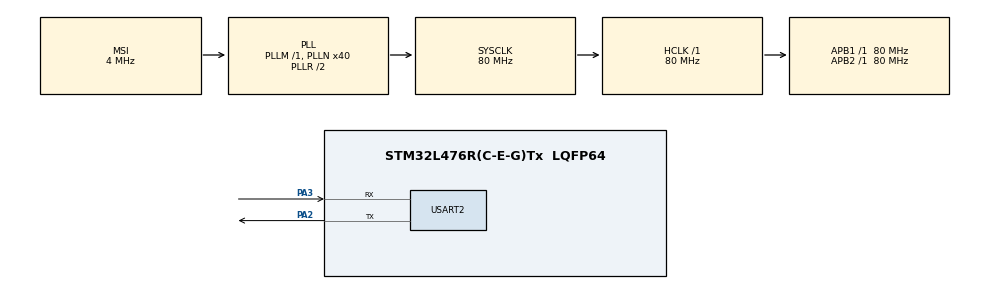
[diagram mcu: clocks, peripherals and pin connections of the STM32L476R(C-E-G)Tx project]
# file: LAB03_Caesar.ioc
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Mcu.Family=STM32L4
Mcu.Name=STM32L476R(C-E-G)Tx
Mcu.Package=LQFP64
NVIC.PriorityGroup=NVIC_PRIORITYGROUP_4
PA2.Mode=Asynchronous
PA2.Signal=USART2_TX
PA3.Mode=Asynchronous
PA3.Signal=USART2_RX
ProjectManager.HeapSize=0x200
ProjectManager.StackSize=0x400
ProjectManager.TargetToolchain=STM32CubeIDE
RCC.AHBFreq_Value=80000000
RCC.APB1Freq_Value=80000000
RCC.APB1TimFreq_Value=80000000
RCC.APB2Freq_Value=80000000
RCC.APB2TimFreq_Value=80000000
RCC.CortexFreq_Value=80000000
RCC.HCLKFreq_Value=80000000
RCC.HSE_VALUE=8000000
RCC.HSI_VALUE=16000000
RCC.LSE_VALUE=32768
RCC.MSI_VALUE=4000000
RCC.PLLN=40
RCC.SYSCLKFreq_VALUE=80000000
RCC.SYSCLKSource=RCC_SYSCLKSOURCE_PLLCLK
RCC.VCOOutputFreq_Value=160000000
USART2.VirtualMode-Asynchronous=VM_ASYNC
board=custom

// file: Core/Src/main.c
/* USER CODE BEGIN Header */
/**
 ******************************************************************************
 * @file           : main.c
 * @brief          : Main program body
 ******************************************************************************
 * @attention
 *
 * Copyright (c) 2023 STMicroelectronics.
 * All rights reserved.
 *
 * This software is licensed under terms that can be found in the LICENSE file
 * in the root directory of this software component.
 * If no LICENSE file comes with this software, it is provided AS-IS.
 *
 ******************************************************************************
 */
/* USER CODE END Header */
#include "main.h"

/* USER CODE BEGIN Includes */
#include <inttypes.h>
#include <stdio.h>
/* USER CODE END Includes */

UART_HandleTypeDef huart2;

void SystemClock_Config(void);
static void MX_GPIO_Init(void);
static void MX_USART2_UART_Init(void);
/* USER CODE BEGIN PFP */
void caesar(void);
/* USER CODE END PFP */

int main(void) {

  /* MCU Configuration--------------------------------------------------------*/

  /* Reset of all peripherals, Initializes the Flash interface and the Systick. */
  HAL_Init();

  /* Configure the system clock */
  SystemClock_Config();

  /* Initialize all configured peripherals */
  MX_GPIO_Init();
  MX_USART2_UART_Init();

  /* Infinite loop */
  /* USER CODE BEGIN WHILE */
  while (1) {
    caesar();
    /* USER CODE END WHILE */

  }
}

void SystemClock_Config(void) {
  RCC_OscInitTypeDef RCC_OscInitStruct = {0};
  RCC_ClkInitTypeDef RCC_ClkInitStruct = {0};

  /** Configure the main internal regulator output voltage
   */
  if (HAL_PWREx_ControlVoltageScaling(PWR_REGULATOR_VOLTAGE_SCALE1) != HAL_OK) {
    Error_Handler();
  }

  /** Initializes the RCC Oscillators according to the specified parameters
   * in the RCC_OscInitTypeDef structure.
   */
  RCC_OscInitStruct.OscillatorType = RCC_OSCILLATORTYPE_MSI;
  RCC_OscInitStruct.MSIState = RCC_MSI_ON;
  RCC_OscInitStruct.MSICalibrationValue = 0;
  RCC_OscInitStruct.MSIClockRange = RCC_MSIRANGE_6;
  RCC_OscInitStruct.PLL.PLLState = RCC_PLL_ON;
  RCC_OscInitStruct.PLL.PLLSource = RCC_PLLSOURCE_MSI;
  RCC_OscInitStruct.PLL.PLLM = 1;
  RCC_OscInitStruct.PLL.PLLN = 40;
  RCC_OscInitStruct.PLL.PLLP = RCC_PLLP_DIV7;
  RCC_OscInitStruct.PLL.PLLQ = RCC_PLLQ_DIV2;
  RCC_OscInitStruct.PLL.PLLR = RCC_PLLR_DIV2;
  if (HAL_RCC_OscConfig(&RCC_OscInitStruct) != HAL_OK) {
    Error_Handler();
  }

  /** Initializes the CPU, AHB and APB buses clocks
   */
  RCC_ClkInitStruct.ClockType = RCC_CLOCKTYPE_HCLK | RCC_CLOCKTYPE_SYSCLK | RCC_CLOCKTYPE_PCLK1 | RCC_CLOCKTYPE_PCLK2;
  RCC_ClkInitStruct.SYSCLKSource = RCC_SYSCLKSOURCE_PLLCLK;
  RCC_ClkInitStruct.AHBCLKDivider = RCC_SYSCLK_DIV1;
  RCC_ClkInitStruct.APB1CLKDivider = RCC_HCLK_DIV1;
  RCC_ClkInitStruct.APB2CLKDivider = RCC_HCLK_DIV1;

  if (HAL_RCC_ClockConfig(&RCC_ClkInitStruct, FLASH_LATENCY_4) != HAL_OK) {
    Error_Handler();
  }
}

static void MX_USART2_UART_Init(void) {

  huart2.Instance = USART2;
  huart2.Init.BaudRate = 115200;
  huart2.Init.WordLength = UART_WORDLENGTH_8B;
  huart2.Init.StopBits = UART_STOPBITS_1;
  huart2.Init.Parity = UART_PARITY_NONE;
  huart2.Init.Mode = UART_MODE_TX_RX;
  huart2.Init.HwFlowCtl = UART_HWCONTROL_NONE;
  huart2.Init.OverSampling = UART_OVERSAMPLING_16;
  huart2.Init.OneBitSampling = UART_ONE_BIT_SAMPLE_DISABLE;
  huart2.AdvancedInit.AdvFeatureInit = UART_ADVFEATURE_NO_INIT;
  if (HAL_UART_Init(&huart2) != HAL_OK) {
    Error_Handler();
  }
}

static void MX_GPIO_Init(void) {

  /* GPIO Ports Clock Enable */
  __HAL_RCC_GPIOA_CLK_ENABLE();

}

/* USER CODE BEGIN 4 */

int _write(int file, char *ptr, int len) {
  (void)file;
  HAL_UART_Transmit(&huart2, (uint8_t *)ptr, len, len * 10);
  return len;
}

#define MAX_STR_LEN 100

void caesar(void) {
  // Buffer to hold the string we receive with extra space for zero termination:
  char input_buffer[MAX_STR_LEN + 1] = {0};

  // =================================
  // === PART 1: Read input string ===
  // =================================

  printf("\r\n");
  printf("Please enter a string, terminated by a period:\r\n");

  unsigned int str_len = 0; // Number of characters already received

  // Loop until there is no more space in the buffer.
  // This is important: Most strings sent will be shorter than the MAX_STR_LEN,
  // but nothing stops the user from sending thousands of characters before
  // sending a period. Without this check we would start writing user data
  // beyond the end of our array - a classic buffer overflow.
  while (str_len < MAX_STR_LEN) {

    // Receive a character:
    // TODO: Receive a single character via UART.
    //       Make sure to check the return value of the HAL function. If there was an error,
    //       use printf to print an error message and return.
    uint8_t next_character;
    if (HAL_UART_Receive(&huart2, &next_character, 1, HAL_MAX_DELAY) != HAL_OK)
      printf("There was an error recieving the last character.");
    // TODO: If you received a '.' stop collecting input:
    if (next_character == '.') {
      break;
    }

    // Otherwise, add the character you received to the input buffer:
    input_buffer[str_len] = (char)next_character;
    str_len++;
  }

  // TODO: Zero-terminate the input string in the buffer:
  input_buffer[++str_len] = '\0';

  printf("\r\n");

  // TODO: Print the string you received to check that part 1 is working:
  printf("Decoding: %s", input_buffer);

  printf("\r\n");

  // ======================
  // === PART 2: Decode ===
  // ======================

  // Buffer to hold the decoded string:
  char output_buffer[MAX_STR_LEN + 1] = {0};

  // For every possible shift (1 to 25), decode the string with the Caesar
  // cipher into the output_buffer. Then print both the current shift
  // and decoded string.
  for (unsigned int shift = 1; shift < 26; shift++) {

    // Decode one character at a time:
    for (unsigned int i = 0; i < str_len; i++) {

      // Grab character to decode:
      char character = input_buffer[i];

      // TODO: If the character is not a letter, put it into the output buffer as is

      if ( !( (64 < character && character < 91) || (96 < character && character < 123) )) {
        output_buffer[i] = character;
        continue;
      }

      // TODO: Determine the position of the letter in the alphabet.
      //       For example, 'A' or 'a' are in position 0, while 'Z' and 'z' have
      //       are in position 25.
      // HINT: Handle upper-case and lower-case letters separately, and make
      //       use of the fact that letters are stored as ASCII-encoded numbers.
      unsigned int position_in_abc = (64 < character && character < 91) ? character - 65 : character - 97;

      // TODO: Determine the decoded character using the Caesar cipher.
      // First add the current shift to the position of the input character in the alphabet.
      // Make sure to handle wrap-around!
      // Then, convert the result position to the actual character.
      unsigned int result_position_in_abc = (position_in_abc + shift) % 26;
      char result_character = result_position_in_abc + 65 + !(64 < character && character < 91) * (97 - 65);

      // TODO: Store the decoded character in the output buffer.
      output_buffer[i] = result_character;
    }

    // TODO: Zero-terminate the output string in the buffer:
    output_buffer[str_len] = '\0';

    // TODO: Print the current shift and decoded string
    printf("current shift: %i, string : %s\r\n", shift, output_buffer);
  }
}
/* USER CODE END 4 */

void Error_Handler(void) {
  __disable_irq();
  while (1) {
  }
}
